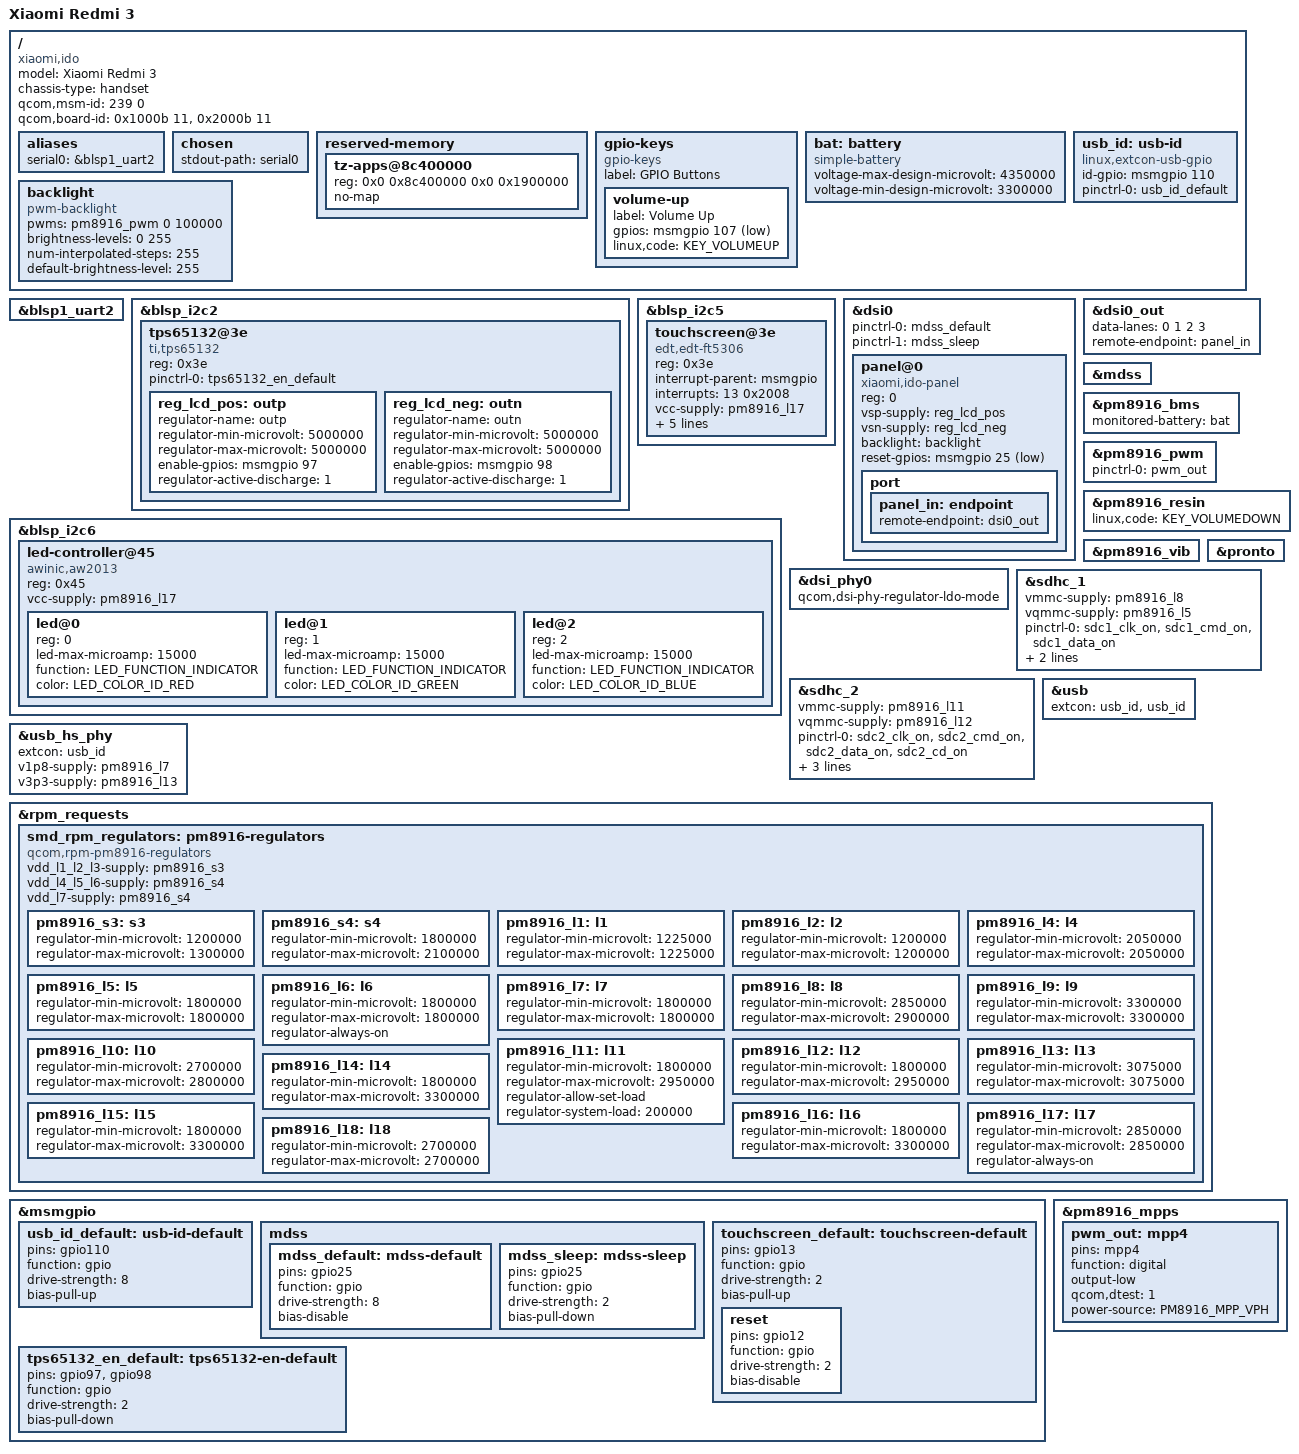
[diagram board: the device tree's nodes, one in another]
// SPDX-License-Identifier: GPL-2.0-only

/dts-v1/;

#include "msm8939.dtsi"
#include "pm8916.dtsi"
#include <dt-bindings/gpio/gpio.h>
#include <dt-bindings/pinctrl/qcom,pmic-mpp.h>
#include <dt-bindings/leds/common.h>

/ {
	model = "Xiaomi Redmi 3";
	compatible = "xiaomi,ido", "qcom,msm8939", "qcom,msm8939-qrd-skuk", "qcom,qrd";
	chassis-type = "handset";
	qcom,msm-id = <239 0>;
	qcom,board-id = <0x1000b 11>, <0x2000b 11>;

	aliases {
		serial0 = &blsp1_uart2;
	};

	chosen {
		stdout-path = "serial0";
/*
		bootargs = "earlycon=tty0 console=tty0";
		#address-cells = <2>;
		#size-cells = <2>;
		ranges;

		framebuffer0: framebuffer@83003000 {
			status= "okay";
			compatible = "simple-framebuffer";
			reg = <0x0 0x83200000 0x0 0x2000000>;
			width = <720>;
			height = <1280>;
			stride = <(720 * 3)>;
			format = "r8g8b8";
		};*/

	};

    reserved-memory {
        /delete-node/ rmtfs@86681000;
		/delete-node/ rfsa@867e0000;
		/delete-node/ tz-apps@86000000;
/*
		cont_splash_mem: framebuffer@83000000 {
			compatible = "removed-dma-pool";
			reg = <0x0 0x83000000 0x0 0x2000000>;
			no-map;
		};*/
        tz-apps@8c400000 {
			reg = <0x0 0x8c400000 0x0 0x1900000>;
			no-map;
		};
	};

    gpio-keys {
		compatible = "gpio-keys";

		pinctrl-names = "default";

		label = "GPIO Buttons";

		volume-up {
			label = "Volume Up";
			gpios = <&msmgpio 107 GPIO_ACTIVE_LOW>;
			linux,code = <KEY_VOLUMEUP>;
		};
	};

    bat: battery {
        compatible = "simple-battery";
        voltage-max-design-microvolt = <4350000>;
		voltage-min-design-microvolt = <3300000>;
    };

    usb_id: usb-id {
		compatible = "linux,extcon-usb-gpio";
		id-gpio = <&msmgpio 110 GPIO_ACTIVE_HIGH>;
		pinctrl-names = "default";
		pinctrl-0 = <&usb_id_default>;
	};

    backlight: backlight {
		compatible = "pwm-backlight";
		pwms = <&pm8916_pwm 0 100000>;

		brightness-levels = <0 255>;
		num-interpolated-steps = <255>;
		default-brightness-level = <255>;
	};
};

&blsp1_uart2 {
	status = "okay";
};

&blsp_i2c2 {
	status = "okay";

	tps65132@3e {
		compatible = "ti,tps65132";
		reg = <0x3e>;

		pinctrl-names = "default";
		pinctrl-0 = <&tps65132_en_default>;

		reg_lcd_pos: outp {
			regulator-name = "outp";
			regulator-min-microvolt = <5000000>;
			regulator-max-microvolt = <5000000>;
			enable-gpios = <&msmgpio 97 GPIO_ACTIVE_HIGH>;
			regulator-active-discharge = <1>;
		};

		reg_lcd_neg: outn {
			regulator-name = "outn";
			regulator-min-microvolt = <5000000>;
			regulator-max-microvolt = <5000000>;
			enable-gpios = <&msmgpio 98 GPIO_ACTIVE_HIGH>;
			regulator-active-discharge = <1>;
		};
	};
};
/*
&blsp_i2c4 {
        #address-cells = <1>;
        #size-cells = <0>;

        cw2015@62 {
            compatible = "cellwise,cw2015";
            reg = <0x62>;
            cellwise,battery-profile = /bits/ 8 <
                0x17 0x67 0x80 0x73 0x6E 0x6C 0x6B 0x63
                0x77 0x51 0x5C 0x58 0x50 0x4C 0x48 0x36
                0x15 0x0C 0x0C 0x19 0x5B 0x7D 0x6F 0x69
                0x69 0x5B 0x0C 0x29 0x20 0x40 0x52 0x59
                0x57 0x56 0x54 0x4F 0x3B 0x1F 0x7F 0x17
                0x06 0x1A 0x30 0x5A 0x85 0x93 0x96 0x2D
                0x48 0x77 0x9C 0xB3 0x80 0x52 0x94 0xCB
                0x2F 0x00 0x64 0xA5 0xB5 0x11 0xF0 0x11
           >;
           cellwise,monitor-interval-ms = <5000>;
           monitored-battery = <&bat>;
           //power-supplies = <&mains_charger>, <&usb_charger>;
       };
    };
*/
&blsp_i2c5 {
	status = "okay";

	touchscreen@3e {
		/* actually FT5336 */
		compatible = "edt,edt-ft5306";
		reg = <0x3e>;

		interrupt-parent = <&msmgpio>;
		interrupts = <13 0x2008>;

		vcc-supply = <&pm8916_l17>;
		iovcc-supply = <&pm8916_l6>;

		reset-gpios = <&msmgpio 12 GPIO_ACTIVE_LOW>;

		touchscreen-size-x = <720>;
		touchscreen-size-y = <1280>;

		pinctrl-names = "default";
		pinctrl-0 = <&touchscreen_default>;
	};
};

&blsp_i2c6 {
	status = "okay";

	led-controller@45 {
		compatible = "awinic,aw2013";
		reg = <0x45>;
		#address-cells = <1>;
		#size-cells = <0>;

		vcc-supply = <&pm8916_l17>;

		led@0 {
			reg = <0>;
			led-max-microamp = <15000>;
			function = LED_FUNCTION_INDICATOR;
			color = <LED_COLOR_ID_RED>;
		};

		led@1 {
			reg = <1>;
			led-max-microamp = <15000>;
			function = LED_FUNCTION_INDICATOR;
			color = <LED_COLOR_ID_GREEN>;
		};

		led@2 {
			reg = <2>;
			led-max-microamp = <15000>;
			function = LED_FUNCTION_INDICATOR;
			color = <LED_COLOR_ID_BLUE>;
		};
	};
};

&dsi0 {
    pinctrl-names = "default", "sleep";
	pinctrl-0 = <&mdss_default>;
	pinctrl-1 = <&mdss_sleep>;

	panel@0 {
		compatible = "xiaomi,ido-panel";
		reg = <0>;

        vsp-supply = <&reg_lcd_pos>;
		vsn-supply = <&reg_lcd_neg>;

		backlight = <&backlight>;
		reset-gpios = <&msmgpio 25 GPIO_ACTIVE_LOW>;

		port {
			panel_in: endpoint {
				remote-endpoint = <&dsi0_out>;
			};
		};
	};
};

&dsi0_out {
	data-lanes = <0 1 2 3>;
	remote-endpoint = <&panel_in>;
};

&dsi_phy0 {
	qcom,dsi-phy-regulator-ldo-mode;
};

&mdss {
	status = "okay";
};

&pm8916_bms {
	status = "okay";

	monitored-battery = <&bat>;
};

&pm8916_pwm {
	status = "okay";
	pinctrl-names = "default";
	pinctrl-0 = <&pwm_out>;
};

&pm8916_resin {
	status = "okay";
	linux,code = <KEY_VOLUMEDOWN>;
};

&pm8916_vib {
	status = "okay";
};

&pronto {
	status = "okay";
};

&sdhc_1 {
	status = "okay";

	vmmc-supply = <&pm8916_l8>;
	vqmmc-supply = <&pm8916_l5>;

	pinctrl-names = "default", "sleep";
	pinctrl-0 = <&sdc1_clk_on &sdc1_cmd_on &sdc1_data_on>;
	pinctrl-1 = <&sdc1_clk_off &sdc1_cmd_off &sdc1_data_off>;
};

&sdhc_2 {
	status = "okay";

	vmmc-supply = <&pm8916_l11>;
	vqmmc-supply = <&pm8916_l12>;

	pinctrl-names = "default", "sleep";
	pinctrl-0 = <&sdc2_clk_on &sdc2_cmd_on &sdc2_data_on &sdc2_cd_on>;
	pinctrl-1 = <&sdc2_clk_off &sdc2_cmd_off &sdc2_data_off &sdc2_cd_off>;

	cd-gpios = <&msmgpio 38 GPIO_ACTIVE_HIGH>;
};

&usb {
	status = "okay";
	extcon = <&usb_id>, <&usb_id>;
};

&usb_hs_phy {
	extcon = <&usb_id>;
    v1p8-supply = <&pm8916_l7>;
	v3p3-supply = <&pm8916_l13>;
};


&rpm_requests {
	smd_rpm_regulators: pm8916-regulators {
		compatible = "qcom,rpm-pm8916-regulators";
		vdd_l1_l2_l3-supply = <&pm8916_s3>;
		vdd_l4_l5_l6-supply = <&pm8916_s4>;
		vdd_l7-supply = <&pm8916_s4>;

		pm8916_s3: s3 {
			regulator-min-microvolt = <1200000>;
			regulator-max-microvolt = <1300000>;
		};

		pm8916_s4: s4 {
			regulator-min-microvolt = <1800000>;
			regulator-max-microvolt = <2100000>;
		};

		pm8916_l1: l1 {
			regulator-min-microvolt = <1225000>;
			regulator-max-microvolt = <1225000>;
		};

		pm8916_l2: l2 {
			regulator-min-microvolt = <1200000>;
			regulator-max-microvolt = <1200000>;
		};

		pm8916_l4: l4 {
			regulator-min-microvolt = <2050000>;
			regulator-max-microvolt = <2050000>;
		};

		pm8916_l5: l5 {
			regulator-min-microvolt = <1800000>;
			regulator-max-microvolt = <1800000>;
		};

		pm8916_l6: l6 {
			regulator-min-microvolt = <1800000>;
			regulator-max-microvolt = <1800000>;
			regulator-always-on;
		};

		pm8916_l7: l7 {
			regulator-min-microvolt = <1800000>;
			regulator-max-microvolt = <1800000>;
		};

		pm8916_l8: l8 {
			regulator-min-microvolt = <2850000>;
			regulator-max-microvolt = <2900000>;
		};

		pm8916_l9: l9 {
			regulator-min-microvolt = <3300000>;
			regulator-max-microvolt = <3300000>;
		};

		pm8916_l10: l10 {
			regulator-min-microvolt = <2700000>;
			regulator-max-microvolt = <2800000>;
		};

		pm8916_l11: l11 {
			regulator-min-microvolt = <1800000>;
			regulator-max-microvolt = <2950000>;
			regulator-allow-set-load;
			regulator-system-load = <200000>;
		};

		pm8916_l12: l12 {
			regulator-min-microvolt = <1800000>;
			regulator-max-microvolt = <2950000>;
		};

		pm8916_l13: l13 {
			regulator-min-microvolt = <3075000>;
			regulator-max-microvolt = <3075000>;
		};

		pm8916_l14: l14 {
			regulator-min-microvolt = <1800000>;
			regulator-max-microvolt = <3300000>;
		};

		pm8916_l15: l15 {
			regulator-min-microvolt = <1800000>;
			regulator-max-microvolt = <3300000>;
		};

		pm8916_l16: l16 {
			regulator-min-microvolt = <1800000>;
			regulator-max-microvolt = <3300000>;
		};

		pm8916_l17: l17 {
			regulator-min-microvolt = <2850000>;
			regulator-max-microvolt = <2850000>;
            regulator-always-on;
		};

		pm8916_l18: l18 {
			regulator-min-microvolt = <2700000>;
			regulator-max-microvolt = <2700000>;
		};
	};
};

&msmgpio {
	usb_id_default: usb-id-default {
		pins = "gpio110";
		function = "gpio";

		drive-strength = <8>;
		bias-pull-up;
	};

    mdss {
		mdss_default: mdss-default {
			pins = "gpio25";
			function = "gpio";

			drive-strength = <8>;
			bias-disable;
		};
		mdss_sleep: mdss-sleep {
			pins = "gpio25";
			function = "gpio";

			drive-strength = <2>;
			bias-pull-down;
		};
	};

    touchscreen_default: touchscreen-default {
		pins = "gpio13";
		function = "gpio";

		drive-strength = <2>;
		bias-pull-up;

		reset {
			pins = "gpio12";
			function = "gpio";

			drive-strength = <2>;
			bias-disable;
		};
	};

    tps65132_en_default: tps65132-en-default {
		pins = "gpio97", "gpio98";
		function = "gpio";

		drive-strength = <2>;
		bias-pull-down;
	};
};

&pm8916_mpps {
	pwm_out: mpp4 {
		pins = "mpp4";
		function = "digital";

		output-low;
		qcom,dtest = <1>;
		power-source = <PM8916_MPP_VPH>;
	};
};

